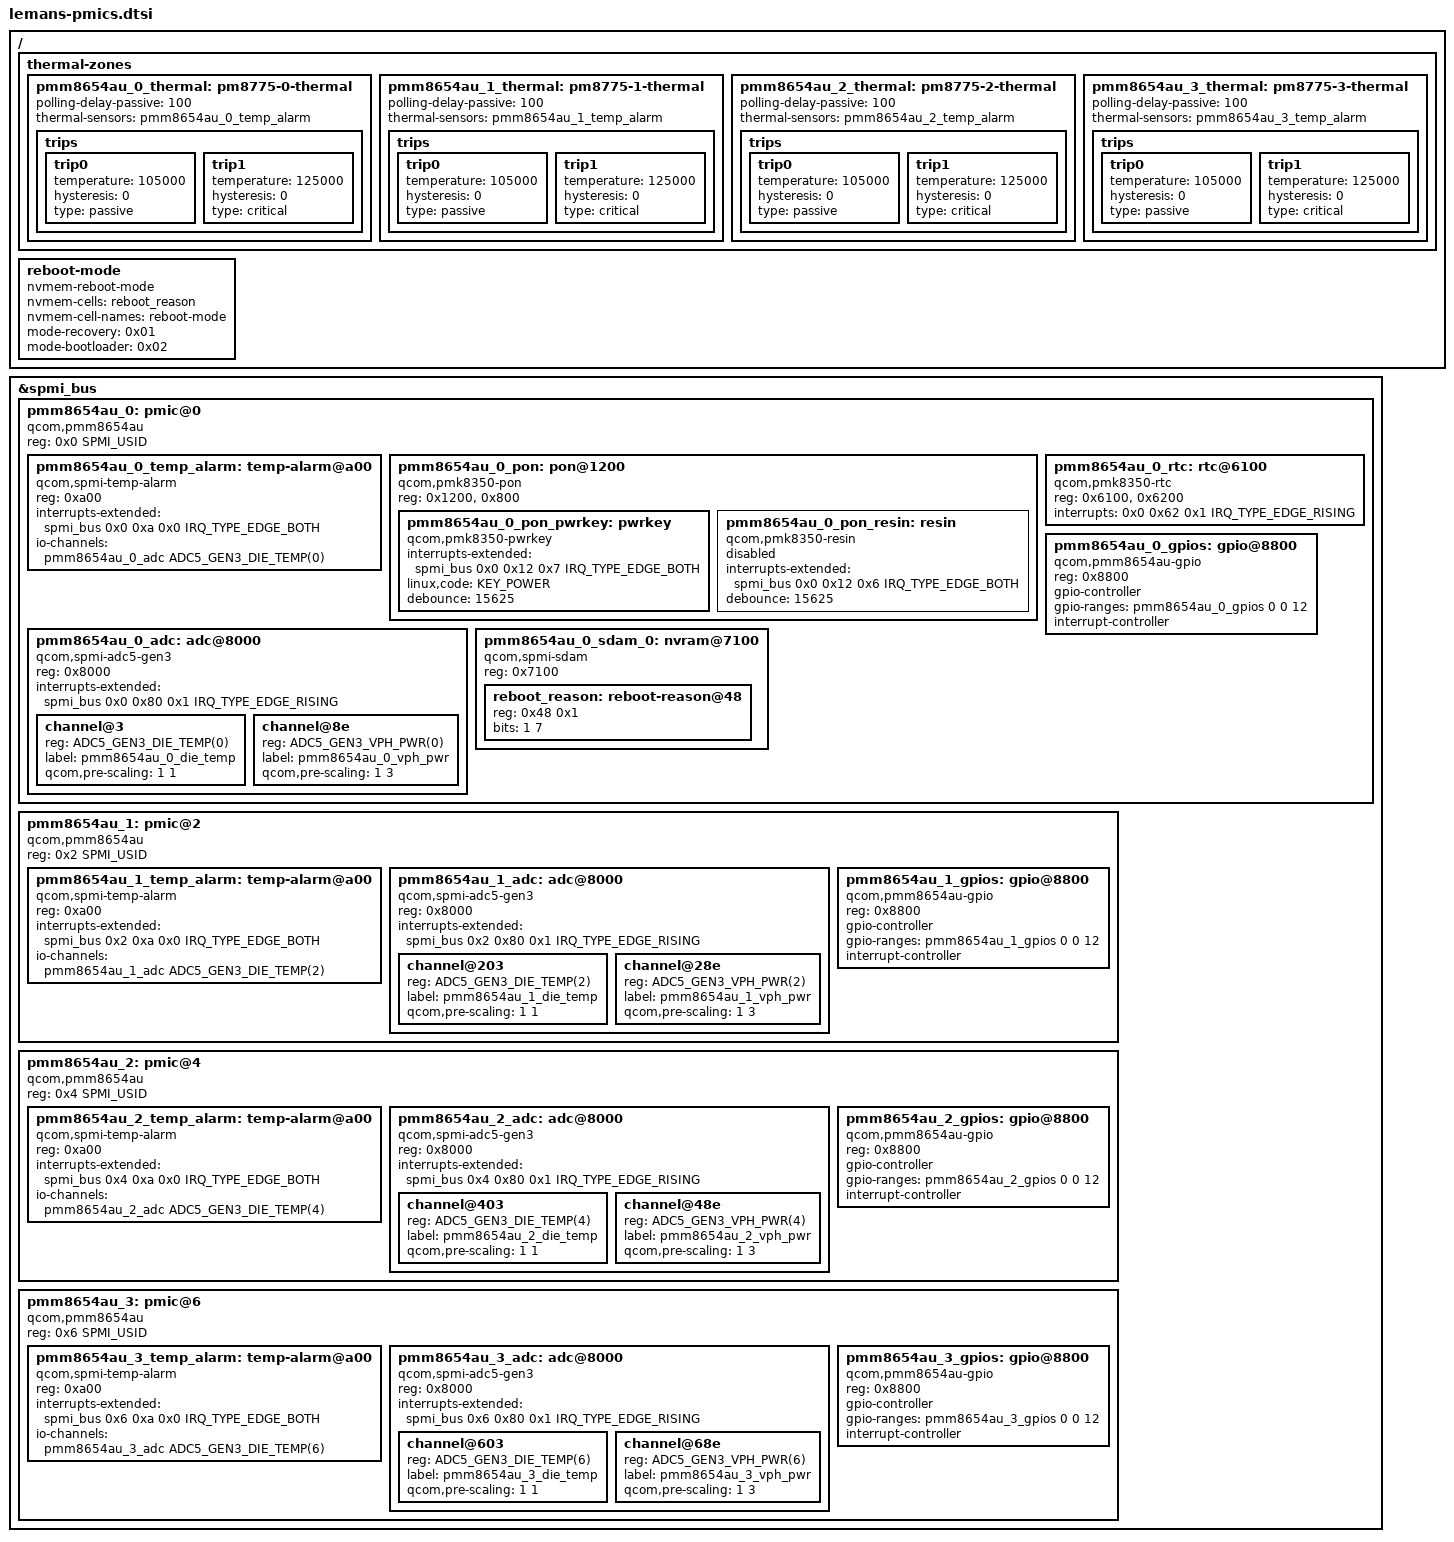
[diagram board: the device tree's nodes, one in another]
// SPDX-License-Identifier: BSD-3-Clause
/*
 * Copyright (c) 2023, Linaro Limited
 */

#include <dt-bindings/input/input.h>
#include <dt-bindings/spmi/spmi.h>
#include "qcom-adc5-gen3.h"

/ {
	thermal-zones {
		pmm8654au_0_thermal: pm8775-0-thermal {
			polling-delay-passive = <100>;

			thermal-sensors = <&pmm8654au_0_temp_alarm>;

			trips {
				trip0 {
					temperature = <105000>;
					hysteresis = <0>;
					type = "passive";
				};

				trip1 {
					temperature = <125000>;
					hysteresis = <0>;
					type = "critical";
				};
			};
		};

		pmm8654au_1_thermal: pm8775-1-thermal {
			polling-delay-passive = <100>;

			thermal-sensors = <&pmm8654au_1_temp_alarm>;

			trips {
				trip0 {
					temperature = <105000>;
					hysteresis = <0>;
					type = "passive";
				};

				trip1 {
					temperature = <125000>;
					hysteresis = <0>;
					type = "critical";
				};
			};
		};

		pmm8654au_2_thermal: pm8775-2-thermal {
			polling-delay-passive = <100>;

			thermal-sensors = <&pmm8654au_2_temp_alarm>;

			trips {
				trip0 {
					temperature = <105000>;
					hysteresis = <0>;
					type = "passive";
				};

				trip1 {
					temperature = <125000>;
					hysteresis = <0>;
					type = "critical";
				};
			};
		};

		pmm8654au_3_thermal: pm8775-3-thermal {
			polling-delay-passive = <100>;

			thermal-sensors = <&pmm8654au_3_temp_alarm>;

			trips {
				trip0 {
					temperature = <105000>;
					hysteresis = <0>;
					type = "passive";
				};

				trip1 {
					temperature = <125000>;
					hysteresis = <0>;
					type = "critical";
				};
			};
		};
	};

	reboot-mode {
		compatible = "nvmem-reboot-mode";
		nvmem-cells = <&reboot_reason>;
		nvmem-cell-names = "reboot-mode";
		mode-recovery = <0x01>;
		mode-bootloader = <0x02>;
	};
};

&spmi_bus {
	pmm8654au_0: pmic@0 {
		compatible = "qcom,pmm8654au", "qcom,spmi-pmic";
		reg = <0x0 SPMI_USID>;
		#address-cells = <1>;
		#size-cells = <0>;

		pmm8654au_0_temp_alarm: temp-alarm@a00 {
			compatible = "qcom,spmi-temp-alarm";
			reg = <0xa00>;
			interrupts-extended = <&spmi_bus 0x0 0xa 0x0 IRQ_TYPE_EDGE_BOTH>;
			#thermal-sensor-cells = <0>;
			io-channels = <&pmm8654au_0_adc ADC5_GEN3_DIE_TEMP(0)>;
			io-channel-names = "thermal";
		};

		pmm8654au_0_pon: pon@1200 {
			compatible = "qcom,pmk8350-pon";
			reg = <0x1200>, <0x800>;
			reg-names = "hlos", "pbs";

			pmm8654au_0_pon_pwrkey: pwrkey {
				compatible = "qcom,pmk8350-pwrkey";
				interrupts-extended = <&spmi_bus 0x0 0x12 0x7 IRQ_TYPE_EDGE_BOTH>;
				linux,code = <KEY_POWER>;
				debounce = <15625>;
			};

			pmm8654au_0_pon_resin: resin {
				compatible = "qcom,pmk8350-resin";
				interrupts-extended = <&spmi_bus 0x0 0x12 0x6 IRQ_TYPE_EDGE_BOTH>;
				debounce = <15625>;
				status = "disabled";
			};
		};

		pmm8654au_0_rtc: rtc@6100 {
			compatible = "qcom,pmk8350-rtc";
			reg = <0x6100>,
			      <0x6200>;
			reg-names = "rtc",
				    "alarm";
			interrupts = <0x0 0x62 0x1 IRQ_TYPE_EDGE_RISING>;
		};

		pmm8654au_0_adc: adc@8000 {
			compatible = "qcom,spmi-adc5-gen3";
			reg = <0x8000>;
			interrupts-extended = <&spmi_bus 0x0 0x80 0x1 IRQ_TYPE_EDGE_RISING>;
			#address-cells = <1>;
			#size-cells = <0>;
			#io-channel-cells = <1>;

			channel@3 {
				reg = <ADC5_GEN3_DIE_TEMP(0)>;
				label = "pmm8654au_0_die_temp";
				qcom,pre-scaling = <1 1>;
			};

			channel@8e {
				reg = <ADC5_GEN3_VPH_PWR(0)>;
				label = "pmm8654au_0_vph_pwr";
				qcom,pre-scaling = <1 3>;
			};
		};

		pmm8654au_0_gpios: gpio@8800 {
			compatible = "qcom,pmm8654au-gpio", "qcom,spmi-gpio";
			reg = <0x8800>;
			gpio-controller;
			gpio-ranges = <&pmm8654au_0_gpios 0 0 12>;
			#gpio-cells = <2>;
			interrupt-controller;
			#interrupt-cells = <2>;
		};

		pmm8654au_0_sdam_0: nvram@7100 {
			compatible = "qcom,spmi-sdam";
			reg = <0x7100>;
			#address-cells = <1>;
			#size-cells = <1>;
			ranges = <0 0x7100 0x100>;

			reboot_reason: reboot-reason@48 {
				reg = <0x48 0x1>;
				bits = <1 7>;
			};
		};
	};

	pmm8654au_1: pmic@2 {
		compatible = "qcom,pmm8654au", "qcom,spmi-pmic";
		reg = <0x2 SPMI_USID>;
		#address-cells = <1>;
		#size-cells = <0>;

		pmm8654au_1_temp_alarm: temp-alarm@a00 {
			compatible = "qcom,spmi-temp-alarm";
			reg = <0xa00>;
			interrupts-extended = <&spmi_bus 0x2 0xa 0x0 IRQ_TYPE_EDGE_BOTH>;
			#thermal-sensor-cells = <0>;
			io-channels = <&pmm8654au_1_adc ADC5_GEN3_DIE_TEMP(2)>;
			io-channel-names = "thermal";
		};

		pmm8654au_1_adc: adc@8000 {
			compatible = "qcom,spmi-adc5-gen3";
			reg = <0x8000>;
			interrupts-extended = <&spmi_bus 0x2 0x80 0x1 IRQ_TYPE_EDGE_RISING>;
			#address-cells = <1>;
			#size-cells = <0>;
			#io-channel-cells = <1>;

			channel@203 {
				reg = <ADC5_GEN3_DIE_TEMP(2)>;
				label = "pmm8654au_1_die_temp";
				qcom,pre-scaling = <1 1>;
			};

			channel@28e {
				reg = <ADC5_GEN3_VPH_PWR(2)>;
				label = "pmm8654au_1_vph_pwr";
				qcom,pre-scaling = <1 3>;
			};
		};

		pmm8654au_1_gpios: gpio@8800 {
			compatible = "qcom,pmm8654au-gpio", "qcom,spmi-gpio";
			reg = <0x8800>;
			gpio-controller;
			gpio-ranges = <&pmm8654au_1_gpios 0 0 12>;
			#gpio-cells = <2>;
			interrupt-controller;
			#interrupt-cells = <2>;
		};
	};

	pmm8654au_2: pmic@4 {
		compatible = "qcom,pmm8654au", "qcom,spmi-pmic";
		reg = <0x4 SPMI_USID>;
		#address-cells = <1>;
		#size-cells = <0>;

		pmm8654au_2_temp_alarm: temp-alarm@a00 {
			compatible = "qcom,spmi-temp-alarm";
			reg = <0xa00>;
			interrupts-extended = <&spmi_bus 0x4 0xa 0x0 IRQ_TYPE_EDGE_BOTH>;
			#thermal-sensor-cells = <0>;
			io-channels = <&pmm8654au_2_adc ADC5_GEN3_DIE_TEMP(4)>;
			io-channel-names = "thermal";
		};

		pmm8654au_2_adc: adc@8000 {
			compatible = "qcom,spmi-adc5-gen3";
			reg = <0x8000>;
			interrupts-extended = <&spmi_bus 0x4 0x80 0x1 IRQ_TYPE_EDGE_RISING>;
			#address-cells = <1>;
			#size-cells = <0>;
			#io-channel-cells = <1>;

			channel@403 {
				reg = <ADC5_GEN3_DIE_TEMP(4)>;
				label = "pmm8654au_2_die_temp";
				qcom,pre-scaling = <1 1>;
			};

			channel@48e {
				reg = <ADC5_GEN3_VPH_PWR(4)>;
				label = "pmm8654au_2_vph_pwr";
				qcom,pre-scaling = <1 3>;
			};
		};

		pmm8654au_2_gpios: gpio@8800 {
			compatible = "qcom,pmm8654au-gpio", "qcom,spmi-gpio";
			reg = <0x8800>;
			gpio-controller;
			gpio-ranges = <&pmm8654au_2_gpios 0 0 12>;
			#gpio-cells = <2>;
			interrupt-controller;
			#interrupt-cells = <2>;
		};
	};

	pmm8654au_3: pmic@6 {
		compatible = "qcom,pmm8654au", "qcom,spmi-pmic";
		reg = <0x6 SPMI_USID>;
		#address-cells = <1>;
		#size-cells = <0>;

		pmm8654au_3_temp_alarm: temp-alarm@a00 {
			compatible = "qcom,spmi-temp-alarm";
			reg = <0xa00>;
			interrupts-extended = <&spmi_bus 0x6 0xa 0x0 IRQ_TYPE_EDGE_BOTH>;
			#thermal-sensor-cells = <0>;
			io-channels = <&pmm8654au_3_adc ADC5_GEN3_DIE_TEMP(6)>;
			io-channel-names = "thermal";
		};

		pmm8654au_3_adc: adc@8000 {
			compatible = "qcom,spmi-adc5-gen3";
			reg = <0x8000>;
			interrupts-extended = <&spmi_bus 0x6 0x80 0x1 IRQ_TYPE_EDGE_RISING>;
			#address-cells = <1>;
			#size-cells = <0>;
			#io-channel-cells = <1>;

			channel@603 {
				reg = <ADC5_GEN3_DIE_TEMP(6)>;
				label = "pmm8654au_3_die_temp";
				qcom,pre-scaling = <1 1>;
			};

			channel@68e {
				reg = <ADC5_GEN3_VPH_PWR(6)>;
				label = "pmm8654au_3_vph_pwr";
				qcom,pre-scaling = <1 3>;
			};
		};

		pmm8654au_3_gpios: gpio@8800 {
			compatible = "qcom,pmm8654au-gpio", "qcom,spmi-gpio";
			reg = <0x8800>;
			gpio-controller;
			gpio-ranges = <&pmm8654au_3_gpios 0 0 12>;
			#gpio-cells = <2>;
			interrupt-controller;
			#interrupt-cells = <2>;
		};
	};
};
